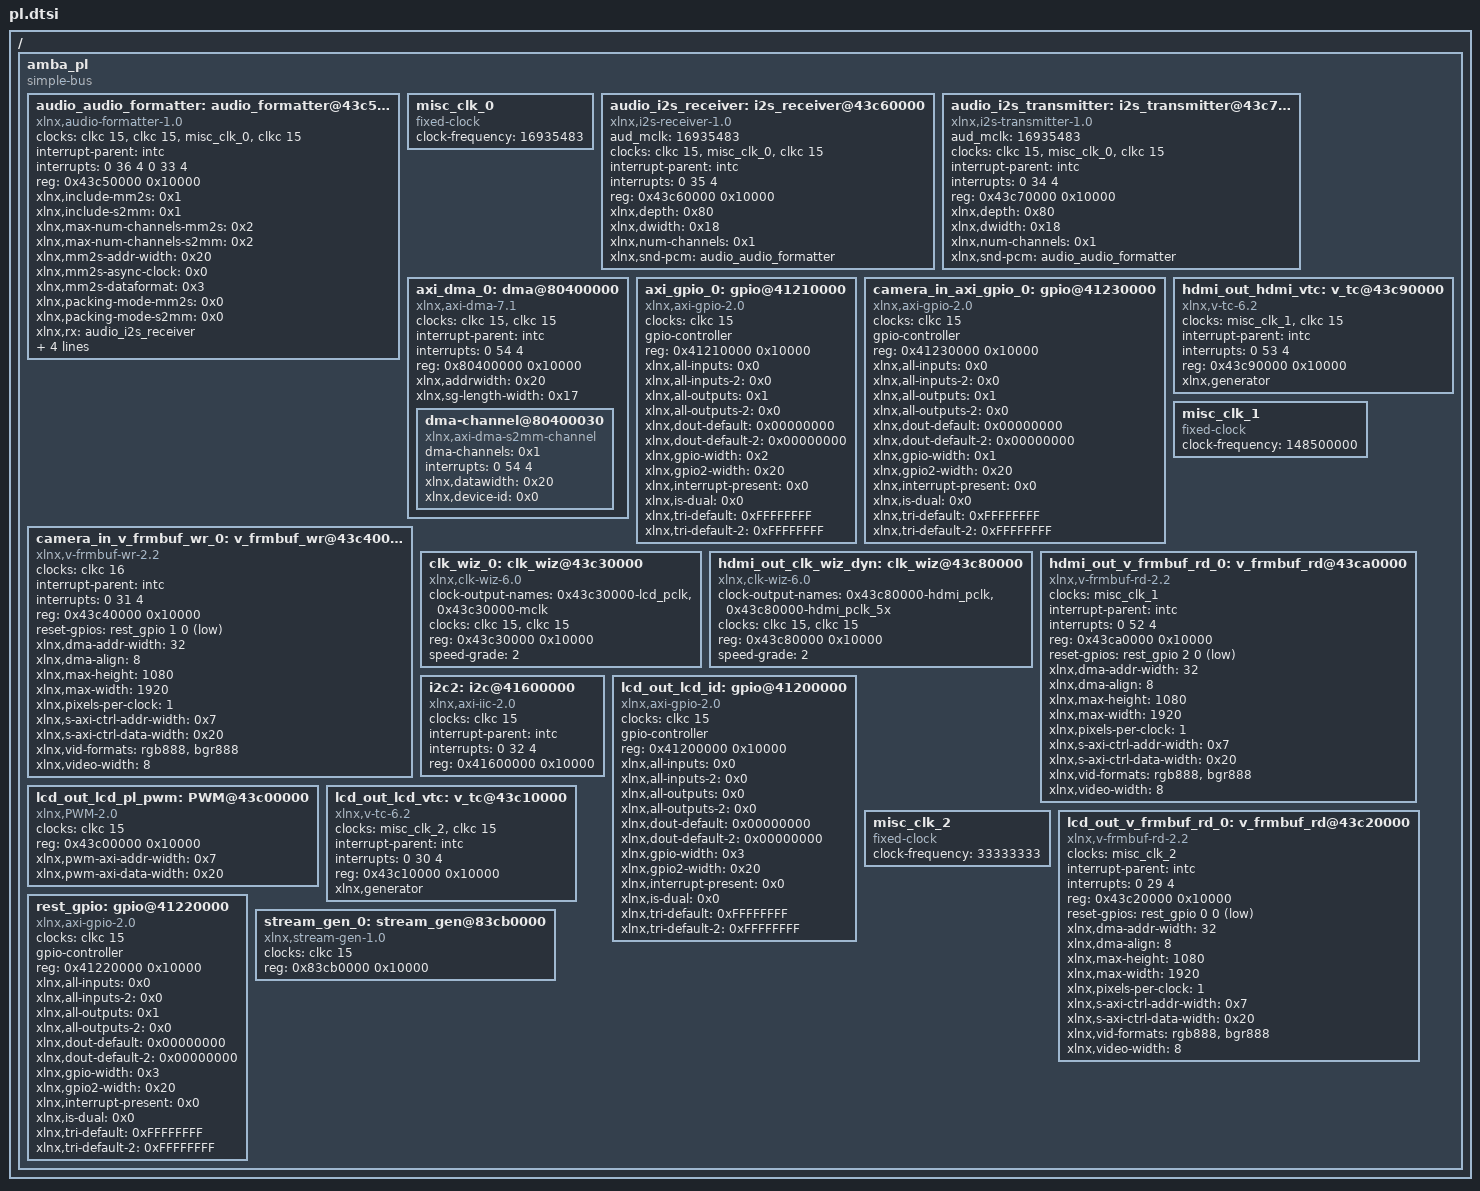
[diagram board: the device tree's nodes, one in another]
/*
 * CAUTION: This file is automatically generated by Xilinx.
 * Version:  
 * Today is: Tue Sep 22 13:37:24 2026
 */


/ {
	amba_pl: amba_pl {
		#address-cells = <1>;
		#size-cells = <1>;
		compatible = "simple-bus";
		ranges ;
		audio_audio_formatter: audio_formatter@43c50000 {
			clock-names = "s_axi_lite_aclk", "m_axis_mm2s_aclk", "aud_mclk", "s_axis_s2mm_aclk";
			clocks = <&clkc 15>, <&clkc 15>, <&misc_clk_0>, <&clkc 15>;
			compatible = "xlnx,audio-formatter-1.0", "xlnx,audio-formatter-1.0";
			interrupt-names = "irq_mm2s", "irq_s2mm";
			interrupt-parent = <&intc>;
			interrupts = <0 36 4 0 33 4>;
			reg = <0x43c50000 0x10000>;
			xlnx,include-mm2s = <0x1>;
			xlnx,include-s2mm = <0x1>;
			xlnx,max-num-channels-mm2s = <0x2>;
			xlnx,max-num-channels-s2mm = <0x2>;
			xlnx,mm2s-addr-width = <0x20>;
			xlnx,mm2s-async-clock = <0x0>;
			xlnx,mm2s-dataformat = <0x3>;
			xlnx,packing-mode-mm2s = <0x0>;
			xlnx,packing-mode-s2mm = <0x0>;
			xlnx,rx = <&audio_i2s_receiver>;
			xlnx,s2mm-addr-width = <0x20>;
			xlnx,s2mm-async-clock = <0x0>;
			xlnx,s2mm-dataformat = <0x1>;
			xlnx,tx = <&audio_i2s_transmitter>;
		};
		misc_clk_0: misc_clk_0 {
			#clock-cells = <0>;
			clock-frequency = <16935483>;
			compatible = "fixed-clock";
		};
		audio_i2s_receiver: i2s_receiver@43c60000 {
			aud_mclk = <16935483>;
			clock-names = "s_axi_ctrl_aclk", "aud_mclk", "m_axis_aud_aclk";
			clocks = <&clkc 15>, <&misc_clk_0>, <&clkc 15>;
			compatible = "xlnx,i2s-receiver-1.0", "xlnx,i2s-receiver-1.0";
			interrupt-names = "irq";
			interrupt-parent = <&intc>;
			interrupts = <0 35 4>;
			reg = <0x43c60000 0x10000>;
			xlnx,depth = <0x80>;
			xlnx,dwidth = <0x18>;
			xlnx,num-channels = <0x1>;
			xlnx,snd-pcm = <&audio_audio_formatter>;
		};
		audio_i2s_transmitter: i2s_transmitter@43c70000 {
			aud_mclk = <16935483>;
			clock-names = "s_axi_ctrl_aclk", "aud_mclk", "s_axis_aud_aclk";
			clocks = <&clkc 15>, <&misc_clk_0>, <&clkc 15>;
			compatible = "xlnx,i2s-transmitter-1.0", "xlnx,i2s-transmitter-1.0";
			interrupt-names = "irq";
			interrupt-parent = <&intc>;
			interrupts = <0 34 4>;
			reg = <0x43c70000 0x10000>;
			xlnx,depth = <0x80>;
			xlnx,dwidth = <0x18>;
			xlnx,num-channels = <0x1>;
			xlnx,snd-pcm = <&audio_audio_formatter>;
		};
		axi_dma_0: dma@80400000 {
			#dma-cells = <1>;
			clock-names = "s_axi_lite_aclk", "m_axi_s2mm_aclk";
			clocks = <&clkc 15>, <&clkc 15>;
			compatible = "xlnx,axi-dma-7.1", "xlnx,axi-dma-1.00.a";
			interrupt-names = "s2mm_introut";
			interrupt-parent = <&intc>;
			interrupts = <0 54 4>;
			reg = <0x80400000 0x10000>;
			xlnx,addrwidth = <0x20>;
			xlnx,sg-length-width = <0x17>;
			dma-channel@80400030 {
				compatible = "xlnx,axi-dma-s2mm-channel";
				dma-channels = <0x1>;
				interrupts = <0 54 4>;
				xlnx,datawidth = <0x20>;
				xlnx,device-id = <0x0>;
			};
		};
		axi_gpio_0: gpio@41210000 {
			#gpio-cells = <3>;
			clock-names = "s_axi_aclk";
			clocks = <&clkc 15>;
			compatible = "xlnx,axi-gpio-2.0", "xlnx,xps-gpio-1.00.a";
			gpio-controller ;
			reg = <0x41210000 0x10000>;
			xlnx,all-inputs = <0x0>;
			xlnx,all-inputs-2 = <0x0>;
			xlnx,all-outputs = <0x1>;
			xlnx,all-outputs-2 = <0x0>;
			xlnx,dout-default = <0x00000000>;
			xlnx,dout-default-2 = <0x00000000>;
			xlnx,gpio-width = <0x2>;
			xlnx,gpio2-width = <0x20>;
			xlnx,interrupt-present = <0x0>;
			xlnx,is-dual = <0x0>;
			xlnx,tri-default = <0xFFFFFFFF>;
			xlnx,tri-default-2 = <0xFFFFFFFF>;
		};
		camera_in_axi_gpio_0: gpio@41230000 {
			#gpio-cells = <3>;
			clock-names = "s_axi_aclk";
			clocks = <&clkc 15>;
			compatible = "xlnx,axi-gpio-2.0", "xlnx,xps-gpio-1.00.a";
			gpio-controller ;
			reg = <0x41230000 0x10000>;
			xlnx,all-inputs = <0x0>;
			xlnx,all-inputs-2 = <0x0>;
			xlnx,all-outputs = <0x1>;
			xlnx,all-outputs-2 = <0x0>;
			xlnx,dout-default = <0x00000000>;
			xlnx,dout-default-2 = <0x00000000>;
			xlnx,gpio-width = <0x1>;
			xlnx,gpio2-width = <0x20>;
			xlnx,interrupt-present = <0x0>;
			xlnx,is-dual = <0x0>;
			xlnx,tri-default = <0xFFFFFFFF>;
			xlnx,tri-default-2 = <0xFFFFFFFF>;
		};
		camera_in_v_frmbuf_wr_0: v_frmbuf_wr@43c40000 {
			#dma-cells = <1>;
			clock-names = "ap_clk";
			clocks = <&clkc 16>;
			compatible = "xlnx,v-frmbuf-wr-2.2", "xlnx,axi-frmbuf-wr-v2.1";
			interrupt-names = "interrupt";
			interrupt-parent = <&intc>;
			interrupts = <0 31 4>;
			reg = <0x43c40000 0x10000>;
			reset-gpios = <&rest_gpio 1 0 1>;
			xlnx,dma-addr-width = <32>;
			xlnx,dma-align = <8>;
			xlnx,max-height = <1080>;
			xlnx,max-width = <1920>;
			xlnx,pixels-per-clock = <1>;
			xlnx,s-axi-ctrl-addr-width = <0x7>;
			xlnx,s-axi-ctrl-data-width = <0x20>;
			xlnx,vid-formats = "rgb888", "bgr888";
			xlnx,video-width = <8>;
		};
		clk_wiz_0: clk_wiz@43c30000 {
			#clock-cells = <1>;
			clock-names = "s_axi_aclk", "clk_in1";
			clock-output-names = "0x43c30000-lcd_pclk", "0x43c30000-mclk";
			clocks = <&clkc 15>, <&clkc 15>;
			compatible = "xlnx,clk-wiz-6.0", "xlnx,clocking-wizard";
			reg = <0x43c30000 0x10000>;
			speed-grade = <2>;
		};
		hdmi_out_clk_wiz_dyn: clk_wiz@43c80000 {
			#clock-cells = <1>;
			clock-names = "s_axi_aclk", "clk_in1";
			clock-output-names = "0x43c80000-hdmi_pclk", "0x43c80000-hdmi_pclk_5x";
			clocks = <&clkc 15>, <&clkc 15>;
			compatible = "xlnx,clk-wiz-6.0", "xlnx,clocking-wizard";
			reg = <0x43c80000 0x10000>;
			speed-grade = <2>;
		};
		hdmi_out_hdmi_vtc: v_tc@43c90000 {
			clock-names = "clk", "s_axi_aclk";
			clocks = <&misc_clk_1>, <&clkc 15>;
			compatible = "xlnx,v-tc-6.2", "xlnx,v-tc-6.1";
			interrupt-names = "irq";
			interrupt-parent = <&intc>;
			interrupts = <0 53 4>;
			reg = <0x43c90000 0x10000>;
			xlnx,generator ;
		};
		misc_clk_1: misc_clk_1 {
			#clock-cells = <0>;
			clock-frequency = <148500000>;
			compatible = "fixed-clock";
		};
		hdmi_out_v_frmbuf_rd_0: v_frmbuf_rd@43ca0000 {
			#dma-cells = <1>;
			clock-names = "ap_clk";
			clocks = <&misc_clk_1>;
			compatible = "xlnx,v-frmbuf-rd-2.2", "xlnx,axi-frmbuf-rd-v2.1";
			interrupt-names = "interrupt";
			interrupt-parent = <&intc>;
			interrupts = <0 52 4>;
			reg = <0x43ca0000 0x10000>;
			reset-gpios = <&rest_gpio 2 0 1>;
			xlnx,dma-addr-width = <32>;
			xlnx,dma-align = <8>;
			xlnx,max-height = <1080>;
			xlnx,max-width = <1920>;
			xlnx,pixels-per-clock = <1>;
			xlnx,s-axi-ctrl-addr-width = <0x7>;
			xlnx,s-axi-ctrl-data-width = <0x20>;
			xlnx,vid-formats = "rgb888", "bgr888";
			xlnx,video-width = <8>;
		};
		i2c2: i2c@41600000 {
			#address-cells = <1>;
			#size-cells = <0>;
			clock-names = "s_axi_aclk";
			clocks = <&clkc 15>;
			compatible = "xlnx,axi-iic-2.0", "xlnx,xps-iic-2.00.a";
			interrupt-names = "iic2intc_irpt";
			interrupt-parent = <&intc>;
			interrupts = <0 32 4>;
			reg = <0x41600000 0x10000>;
		};
		lcd_out_lcd_id: gpio@41200000 {
			#gpio-cells = <3>;
			clock-names = "s_axi_aclk";
			clocks = <&clkc 15>;
			compatible = "xlnx,axi-gpio-2.0", "xlnx,xps-gpio-1.00.a";
			gpio-controller ;
			reg = <0x41200000 0x10000>;
			xlnx,all-inputs = <0x0>;
			xlnx,all-inputs-2 = <0x0>;
			xlnx,all-outputs = <0x0>;
			xlnx,all-outputs-2 = <0x0>;
			xlnx,dout-default = <0x00000000>;
			xlnx,dout-default-2 = <0x00000000>;
			xlnx,gpio-width = <0x3>;
			xlnx,gpio2-width = <0x20>;
			xlnx,interrupt-present = <0x0>;
			xlnx,is-dual = <0x0>;
			xlnx,tri-default = <0xFFFFFFFF>;
			xlnx,tri-default-2 = <0xFFFFFFFF>;
		};
		lcd_out_lcd_pl_pwm: PWM@43c00000 {
			clock-names = "pwm_axi_aclk";
			clocks = <&clkc 15>;
			compatible = "xlnx,PWM-2.0";
			reg = <0x43c00000 0x10000>;
			xlnx,pwm-axi-addr-width = <0x7>;
			xlnx,pwm-axi-data-width = <0x20>;
		};
		lcd_out_lcd_vtc: v_tc@43c10000 {
			clock-names = "clk", "s_axi_aclk";
			clocks = <&misc_clk_2>, <&clkc 15>;
			compatible = "xlnx,v-tc-6.2", "xlnx,v-tc-6.1";
			interrupt-names = "irq";
			interrupt-parent = <&intc>;
			interrupts = <0 30 4>;
			reg = <0x43c10000 0x10000>;
			xlnx,generator ;
		};
		misc_clk_2: misc_clk_2 {
			#clock-cells = <0>;
			clock-frequency = <33333333>;
			compatible = "fixed-clock";
		};
		lcd_out_v_frmbuf_rd_0: v_frmbuf_rd@43c20000 {
			#dma-cells = <1>;
			clock-names = "ap_clk";
			clocks = <&misc_clk_2>;
			compatible = "xlnx,v-frmbuf-rd-2.2", "xlnx,axi-frmbuf-rd-v2.1";
			interrupt-names = "interrupt";
			interrupt-parent = <&intc>;
			interrupts = <0 29 4>;
			reg = <0x43c20000 0x10000>;
			reset-gpios = <&rest_gpio 0 0 1>;
			xlnx,dma-addr-width = <32>;
			xlnx,dma-align = <8>;
			xlnx,max-height = <1080>;
			xlnx,max-width = <1920>;
			xlnx,pixels-per-clock = <1>;
			xlnx,s-axi-ctrl-addr-width = <0x7>;
			xlnx,s-axi-ctrl-data-width = <0x20>;
			xlnx,vid-formats = "rgb888", "bgr888";
			xlnx,video-width = <8>;
		};
		rest_gpio: gpio@41220000 {
			#gpio-cells = <3>;
			clock-names = "s_axi_aclk";
			clocks = <&clkc 15>;
			compatible = "xlnx,axi-gpio-2.0", "xlnx,xps-gpio-1.00.a";
			gpio-controller ;
			reg = <0x41220000 0x10000>;
			xlnx,all-inputs = <0x0>;
			xlnx,all-inputs-2 = <0x0>;
			xlnx,all-outputs = <0x1>;
			xlnx,all-outputs-2 = <0x0>;
			xlnx,dout-default = <0x00000000>;
			xlnx,dout-default-2 = <0x00000000>;
			xlnx,gpio-width = <0x3>;
			xlnx,gpio2-width = <0x20>;
			xlnx,interrupt-present = <0x0>;
			xlnx,is-dual = <0x0>;
			xlnx,tri-default = <0xFFFFFFFF>;
			xlnx,tri-default-2 = <0xFFFFFFFF>;
		};
		stream_gen_0: stream_gen@83cb0000 {
			clock-names = "s_axi_aclk";
			clocks = <&clkc 15>;
			compatible = "xlnx,stream-gen-1.0";
			reg = <0x83cb0000 0x10000>;
		};
	};
};
